# ADSP-2183xW_HPC register map
Vendor: Analog Devices; Series: ADSP-2183xW_HPC; File version: 3.0.3.517
CPU: 
Registers are 32-bit, read-write, reset 0x0 unless marked. A register's access mark holds for its fields unless they carry their own. Offsets are from the block's base; [hi:lo] are bit positions; {n}, {i} and the like mark numbered series.

## SPDIF0 — The S/PDIF module
Base 0x310C9000
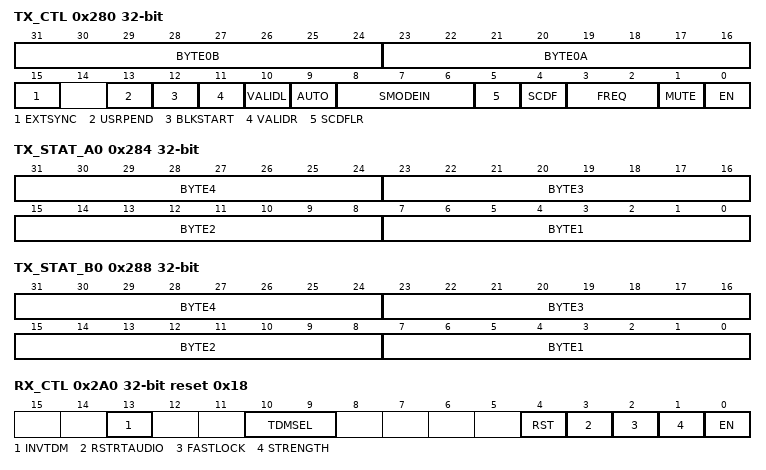
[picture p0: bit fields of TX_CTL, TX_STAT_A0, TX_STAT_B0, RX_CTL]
0x280 TX_CTL — Transmit Control Register
  [31:24] BYTE0B range 0x00000000..0x000000FF — Channel Status Byte for Subframe B
  [23:16] BYTE0A range 0x00000000..0x000000FF — Channel Status Byte for Subframe A
  [15] EXTSYNC range 0x00000000..0x00000001 — External Sync Enable
  [13] USRPEND ro — User Bits Pending
  [12] BLKSTART ro — Block Start
  [11] VALIDR range 0x00000000..0x00000001 — Validity Bit B
  [10] VALIDL — Validity Bit A
  [9] AUTO range 0x00000000..0x00000001 — Automatically Generate Block Start
  [8:6] SMODEIN — Serial Data Input Format
  [5] SCDFLR — Select L/R Single-Channel, Double-Frequency Mode
  [4] SCDF — Single-Channel, Double-Frequency Mode Enable
  [3:2] FREQ — Frequency Multiplier
  [1] MUTE
  [0] EN — Transmitter Enable
0x284 TX_STAT_A0 — Transmit Status A0 Register
  [8n-1:8n-8] BYTE{n} range 0x00000000..0x000000FF (n=1..4) — Byte {n} Sub Frame A
0x288 TX_STAT_B0 — Transmit Status B0 Register
  [8n-1:8n-8] BYTE{n} range 0x00000000..0x000000FF (n=1..4) — Byte {n} Sub Frame B
0x2A0 RX_CTL reset 0x18 — Receive Control
  [13] INVTDM range 0x00000000..0x00000001 — Invert TDM clock
  [10:9] TDMSEL range 0x00000000..0x00000003 — Select TDM clock frequency
  [4] RST — Reset SPDIF Receiver
  [3] RSTRTAUDIO — Restart Audio
  [2] FASTLOCK — Fast Lock Select
    0=NORMAL (Enable normal mode); 1=FAST (Enable fast mode)
  [1] STRENGTH — FS strength Control
    0=STRONG (Enable strong mode); 1=WEAK (Enable weak mode)
  [0] EN — SPDIF Receiver Enable
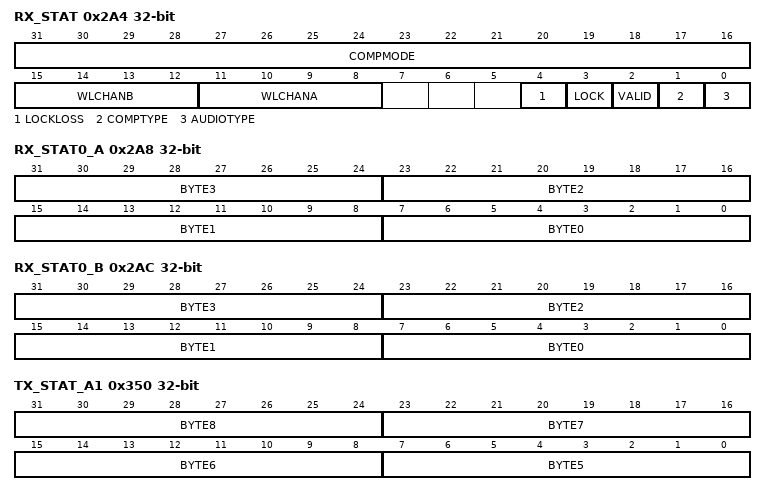
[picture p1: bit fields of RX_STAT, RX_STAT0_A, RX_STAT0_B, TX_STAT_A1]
0x2A4 RX_STAT — Receive Status Register
  [31:16] COMPMODE ro — Compression Mode
  [15:12] WLCHANB ro — Word Length Channel B
  [11:8] WLCHANA ro — Word Length Channel A
  [4] LOCKLOSS ro — Loss of Lock (sticky)
  [3] LOCK ro — Lock Receiver
  [2] VALID ro — Validity Bit
  [1] COMPTYPE ro — Compression Type
  [0] AUDIOTYPE ro
0x2A8 RX_STAT0_A — Receive Status A0 Register
  [8n+7:8n] BYTE{n} ro (n=0..3) — CS Byte {n}
0x2AC RX_STAT0_B — Receive Status B0 Register
  [8n+7:8n] BYTE{n} ro (n=0..3) — CS Byte {n}
0x2B0 RX_STAT1_A — Receive Status A1 Register
  [7:0] BYTE4 ro — CS Byte 4
0x2B4 RX_STAT1_B — Receive Status B1 Register
  [7:0] BYTE4 ro — CS Byte 4
0x350 TX_STAT_A1 — Transmit Status A1 Register
  [8n-33:8n-40] BYTE{n} range 0x00000000..0x000000FF (n=5..8) — Byte {n} Sub Frame A
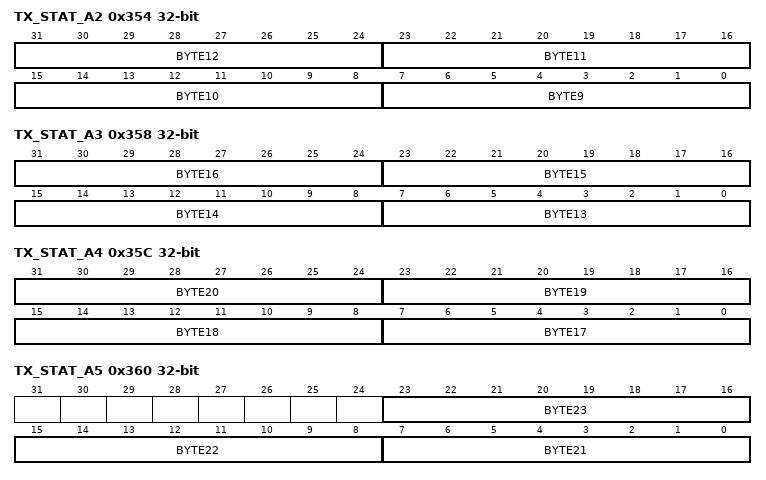
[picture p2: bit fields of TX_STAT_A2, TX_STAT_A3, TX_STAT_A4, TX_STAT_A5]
0x354 TX_STAT_A2 — Transmit Status A2 Register
  [8n-65:8n-72] BYTE{n} range 0x00000000..0x000000FF (n=9..12) — Byte {n} Sub Frame A
0x358 TX_STAT_A3 — Transmit Status A3 Register
  [8n-97:8n-104] BYTE{n} range 0x00000000..0x000000FF (n=13..16) — Byte {n} Sub Frame A
0x35C TX_STAT_A4 — Transmit Status A4 Register
  [8n-129:8n-136] BYTE{n} range 0x00000000..0x000000FF (n=17..20) — Byte {n} Sub Frame A
0x360 TX_STAT_A5 — Transmit Status A5 Register
  [23:16] BYTE23 range 0x00000000..0x000000FF — Byte 23 Sub Frame A
  [15:8] BYTE22 range 0x00000000..0x000000FF — Byte 22 Sub Frame A
  [7:0] BYTE21 range 0x00000000..0x000000FF — Byte 21 Sub Frame A
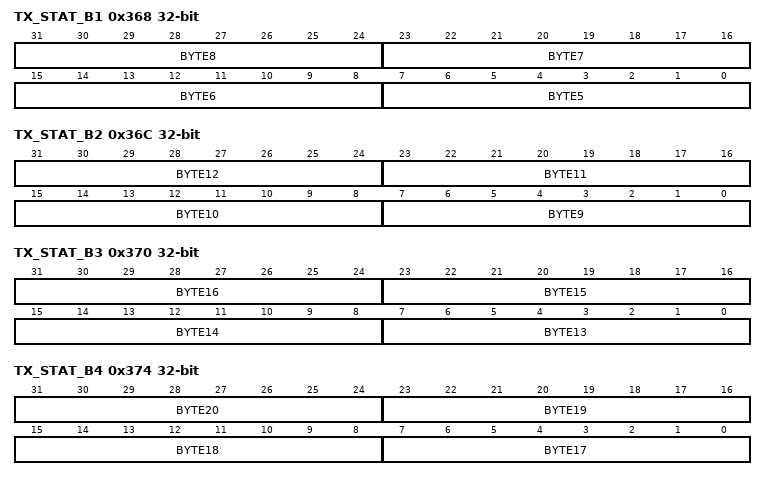
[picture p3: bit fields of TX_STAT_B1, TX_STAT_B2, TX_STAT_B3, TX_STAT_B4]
0x368 TX_STAT_B1 — Transmit Status B1 Register
  [8n-33:8n-40] BYTE{n} range 0x00000000..0x000000FF (n=5..8) — Byte {n} Sub Frame B
0x36C TX_STAT_B2 — Transmit Status B2 Register
  [8n-65:8n-72] BYTE{n} range 0x00000000..0x000000FF (n=9..12) — Byte {n} Sub Frame B
0x370 TX_STAT_B3 — Transmit Status B3 Register
  [8n-97:8n-104] BYTE{n} range 0x00000000..0x000000FF (n=13..16) — Byte {n} Sub Frame B
0x374 TX_STAT_B4 — Transmit Status B4 Register
  [8n-129:8n-136] BYTE{n} range 0x00000000..0x000000FF (n=17..20) — Byte {n} Sub Frame B
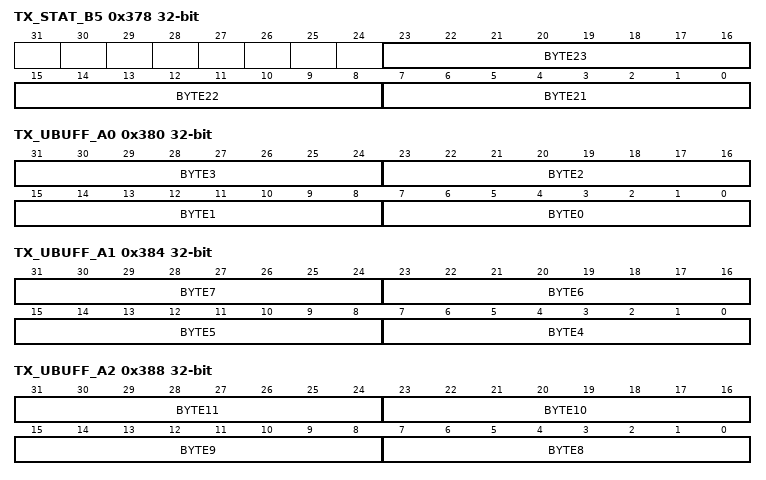
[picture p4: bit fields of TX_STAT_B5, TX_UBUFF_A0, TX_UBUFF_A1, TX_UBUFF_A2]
0x378 TX_STAT_B5 — Transmit Status B5 Register
  [23:16] BYTE23 range 0x00000000..0x000000FF — Byte 23 Sub Frame B
  [15:8] BYTE22 range 0x00000000..0x000000FF — Byte 22 Sub Frame B
  [7:0] BYTE21 range 0x00000000..0x000000FF — Byte 21 Sub Frame B
0x380 TX_UBUFF_A0 — Transmit User Buffer A0 Register
  [31:24] BYTE3 range 0x00000000..0x000000FF — Byte 3 of Subframe A User Bit Buffer
  [23:16] BYTE2 range 0x00000000..0x000000FF — Byte 2 Sub Frame A
  [15:8] BYTE1 range 0x00000000..0x000000FF — Byte 1 Sub Frame A
  [7:0] BYTE0 range 0x00000000..0x000000FF — Byte 0 Sub Frame A
0x384 TX_UBUFF_A1 — Transmit User Buffer A1 Register
  [8n-25:8n-32] BYTE{n} range 0x00000000..0x000000FF (n=4..7) — Byte {n} Sub Frame A
0x388 TX_UBUFF_A2 — Transmit User Buffer A2 Register
  [8n-57:8n-64] BYTE{n} range 0x00000000..0x000000FF (n=8..11) — Byte {n} Sub Frame A
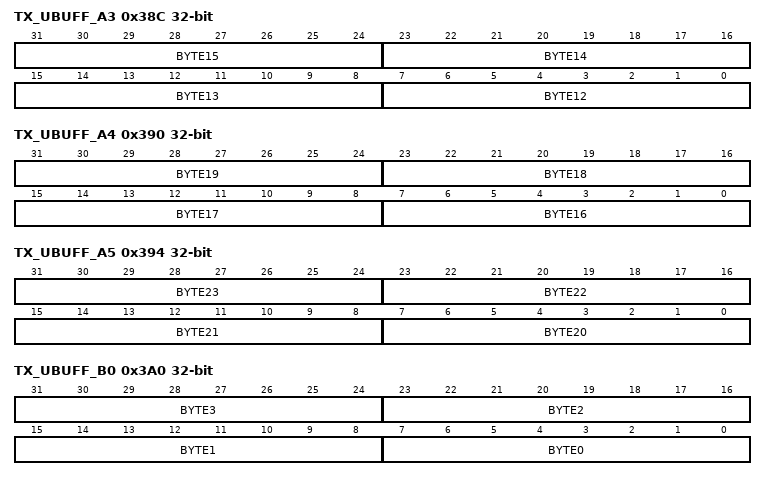
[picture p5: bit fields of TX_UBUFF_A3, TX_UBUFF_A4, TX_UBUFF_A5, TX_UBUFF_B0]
0x38C TX_UBUFF_A3 — Transmit User Buffer A3 Register
  [8n-89:8n-96] BYTE{n} range 0x00000000..0x000000FF (n=12..15) — Byte {n} Sub Frame A
0x390 TX_UBUFF_A4 — Transmit User Buffer A4 Register
  [8n-121:8n-128] BYTE{n} range 0x00000000..0x000000FF (n=16..19) — Byte {n} Sub Frame A
0x394 TX_UBUFF_A5 — Transmit User Buffer A5 Register
  [8n-153:8n-160] BYTE{n} range 0x00000000..0x000000FF (n=20..23) — Byte {n} Sub Frame A
0x3A0 TX_UBUFF_B0 — Transmit User Buffer B0 Register
  [8n+7:8n] BYTE{n} range 0x00000000..0x000000FF (n=0..3) — Byte {n} Sub Frame B
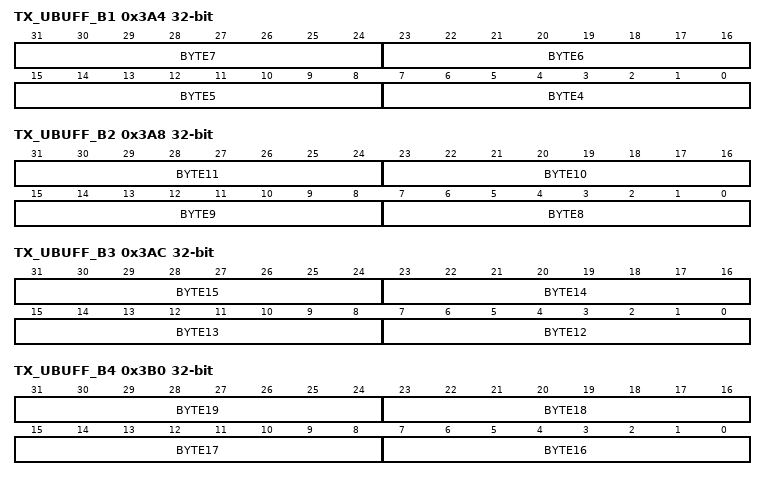
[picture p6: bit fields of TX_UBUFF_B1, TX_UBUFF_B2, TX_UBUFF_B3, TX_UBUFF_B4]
0x3A4 TX_UBUFF_B1 — Transmit User Buffer B1 Register
  [8n-25:8n-32] BYTE{n} range 0x00000000..0x000000FF (n=4..7) — Byte {n} Sub Frame B
0x3A8 TX_UBUFF_B2 — Transmit User Buffer B2 Register
  [8n-57:8n-64] BYTE{n} range 0x00000000..0x000000FF (n=8..11) — Byte {n} Sub Frame B
0x3AC TX_UBUFF_B3 — Transmit User Buffer B3 Register
  [8n-89:8n-96] BYTE{n} range 0x00000000..0x000000FF (n=12..15) — Byte {n} Sub Frame B
0x3B0 TX_UBUFF_B4 — Transmit User Buffer B4 Register
  [8n-121:8n-128] BYTE{n} range 0x00000000..0x000000FF (n=16..19) — Byte {n} Sub Frame B
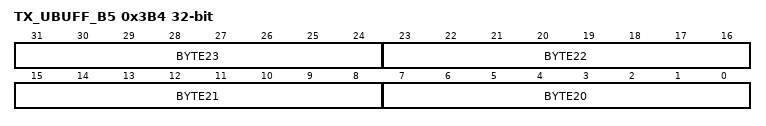
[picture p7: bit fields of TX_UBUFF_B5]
0x3B4 TX_UBUFF_B5 — Transmit User Buffer B5 Register
  [8n-153:8n-160] BYTE{n} range 0x00000000..0x000000FF (n=20..23) — Byte {n} Sub Frame B
0x3BC TX_USRUPDT — User Bit Update Register
  [0] EN ro — Enable

## SPDIF1 — The S/PDIF module
Base 0x310CA000
Registers as SPDIF0; these are added or differ:
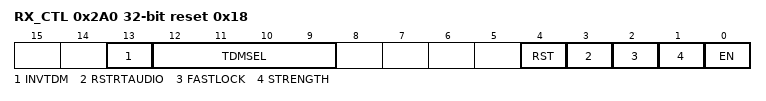
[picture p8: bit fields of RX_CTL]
0x2A0 RX_CTL reset 0x18 — Receive Control
  [13] INVTDM range 0x00000000..0x00000001 — Invert TDM clock
  [12:9] TDMSEL range 0x00000000..0x0000000F — Select TDM clock frequency
  [4] RST — Reset SPDIF Receiver
  [3] RSTRTAUDIO — Restart Audio
  [2] FASTLOCK — Fast Lock Select
    0=NORMAL (Enable normal mode); 1=FAST (Enable fast mode)
  [1] STRENGTH — FS strength Control
    0=STRONG (Enable strong mode); 1=WEAK (Enable weak mode)
  [0] EN — SPDIF Receiver Enable
